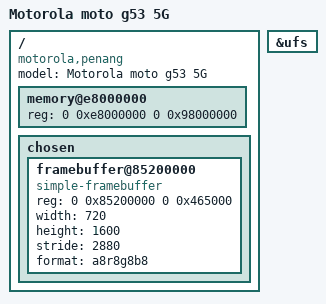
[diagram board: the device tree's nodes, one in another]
/dts-v1/;
/include/ "sm4350.dtsi"

/ {
    model = "Motorola moto g53 5G";
    compatible = "motorola,penang", "qcom,holi";

    // DRAM (ABL /memory): <0x80000000 0x3dd00000>, <0xc0000000 1G>, <0x1_00000000 2G>. XNU gets 0xe8000000-0x180000000:
    // below it TZ apps (0xc1800000), removed_region (0xc0000000-0xc7100000) and the GPU pool (0xc8000000-0xe8000000),
    // reserved in the UEFI memory map (uefi-penang).
    memory@e8000000 {
        device_type = "memory";
        reg = <0 0xe8000000 0 0x98000000>;
    };

    chosen {
        // The ABL's continuous-splash panel: 720x1600 BGRA, kept alive by uefi-penang's PenangDisplayKeepDxe.
        framebuffer@85200000 {
            compatible = "simple-framebuffer";
            reg = <0 0x85200000 0 0x465000>;
            width = <720>;
            height = <1600>;
            stride = <2880>;
            format = "a8r8g8b8";
        };
    };
};

&ufs { status = "okay"; };
